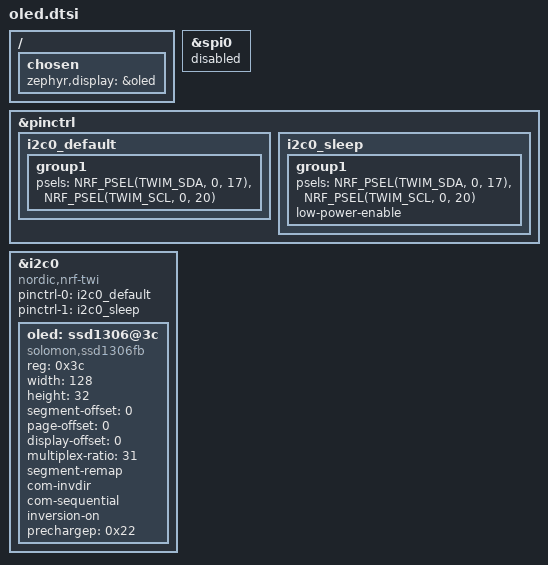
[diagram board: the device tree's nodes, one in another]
/* Display: I2C SSD1306 OLED, 128x32.
   Values taken verbatim from the vendor's own OLED firmware:
   github.com/a741725193/zmk-corne-oled -> boards/shields/eyelash_corne/eyelash_corne.dtsi
   nRF52840 shares one peripheral at 0x40003000 between spi0 and i2c0, so the
   nice!view SPI bus must be disabled for the OLED's I2C bus to work. */
&spi0 { status = "disabled"; };

&pinctrl {
    i2c0_default: i2c0_default {
        group1 { psels = <NRF_PSEL(TWIM_SDA, 0, 17)>, <NRF_PSEL(TWIM_SCL, 0, 20)>; };
    };
    i2c0_sleep: i2c0_sleep {
        group1 { psels = <NRF_PSEL(TWIM_SDA, 0, 17)>, <NRF_PSEL(TWIM_SCL, 0, 20)>; low-power-enable; };
    };
};

&i2c0 {
    status = "okay";
    compatible = "nordic,nrf-twi";
    pinctrl-0 = <&i2c0_default>;
    pinctrl-1 = <&i2c0_sleep>;
    pinctrl-names = "default", "sleep";

    oled: ssd1306@3c {
        compatible = "solomon,ssd1306fb";
        reg = <0x3c>;
        width = <128>;
        height = <32>;
        segment-offset = <0>;
        page-offset = <0>;
        display-offset = <0>;
        multiplex-ratio = <31>;
        segment-remap;
        com-invdir;
        com-sequential;
        inversion-on;
        prechargep = <0x22>;
    };
};

/ { chosen { zephyr,display = &oled; }; };
